# LKS32MC08x register map
Vendor: Linko Ltd.; Series: LKS32MC08x; File version: 1.0
ARM 32-bit Cortex-M0 Microcontroller based device, CPU clock up to 96MHz, etc.
CPU: CM0 r1p0, little endian, MPU, no FPU, 3 interrupt priority bits
Registers are 32-bit, read-write, reset 0x0 unless marked. A register's access mark holds for its fields unless they carry their own. Offsets are from the block's base; lines under a group give offsets from that group; [hi:lo] are bit positions; {n}, {i} and the like mark numbered series; 'fields as' and 'values as' point back to an identical list; <NAME> marks a mode.

## Memory map
0x40000000 SYS size 0x100 — SYS registers
0x40000400 FLASH size 0x40 — FLASH registers
0x40010000 SPI size 0x100 — SPI registers
0x40010400 I2C size 0x100 — I2C registers
0x40010C00 CMP size 0x100 — CMP registers
0x40011000 HALL size 0x100 — HALL registers
0x40011400 ADC0 size 0x100 — ADC0 registers
0x40011800 TIMER0 size 0x20 — TIMER0 registers
0x40011820 TIMER1 size 0x20 — TIMER1 registers
0x40011840 TIMER2 size 0x20 — TIMER2 registers
0x40011860 TIMER3 size 0x20 — TIMER3 registers
0x40011880 ENCODER0 size 0x10 — ENCODER0 registers
0x40011890 ENCODER1 size 0x10 — ENCODER1 registers
0x400118A0 UTIMER_CTRL size 0x60 — UTIMER_CTRL registers
0x40011C00 MCPWM size 0x100 — MCPWM registers
0x40012000 GPIO size 0x200 — GPIO registers
0x40012400 CRC size 0x100 — CRC registers
0x40012800 UART0 size 0x100 — UART0 registers
0x40012C00 UART1 size 0x100 — UART1 registers
0x40013000 DMA size 0x100 — DMA registers
0x40013400 CAN size 0x2000 — CAN registers
0x40013800 SIF size 0x100 — SIF registers
0x40014000 DSP size 0x2000 — DSP registers

## Interrupts
0 TIMER0
1 TIMER1
2 TIMER2
3 TIMER3
4 ENCODER0
5 ENCODER1
6 I2C0 (I2C)
7 GPIO
8 UART0
9 HALL
10 SPI0 (SPI)
11 ADC0
12 DSP
13 MCPWM
14 UART1
15 CMP
16 WAKE (SYS)
17 PWRDN (SYS)
18 DMA
19 CAN
20 SIF

## FLASH — FLASH registers
Base 0x40000400
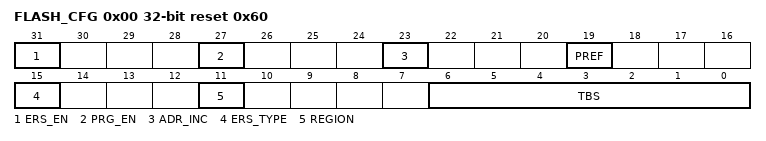
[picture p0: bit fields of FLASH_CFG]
0x00 FLASH_CFG reset 0x60 — Flash Configure Register
  [31] ERS_EN — Flash erase operation is enabled or not
    0=Disabled (Erase is disabled); 1=Enabled (Erase is enabled)
  [27] PRG_EN — Flash program operation is enabled or not
    0=Disabled (Program is disabled); 1=Enabled (Program is enabled)
  [23] ADR_INC — Flash address is incremented automatically or not during sequent access
    0=Disabled (Address incrementation is disabled); 1=Enabled (Address incrementation is enabled)
  [19] PREF — Prefetch Function Enable or Disable
    0=Disabled (Prefetch is disabled); 1=Enabled (Prefetch is enabled)
  [15] ERS_TYPE — Erase Type: Sector/Full
    0=Sector Erase; 1=Full Erase
  [11] REGION — Access Main or NVR
    0=Main access; 1=NVR (NVR access)
  [6:0] TBS — Program/Erase timer baseline
    96=96MHz (P/E Timer value @ 96Mhz); 47=48MHz (P/E Timer value @ 48Mhz); 23=24MHz (P/E Timer value @ 24Mhz); 11=12MHz (P/E Timer value @ 12Mhz)
0x04 FLASH_ADDR — Flash Access Address Register
0x08 FLASH_WDATA — Flash Write Data Register
0x0C FLASH_RDATA ro — Flash Write Data Register
0x10 FLASH_ERASE wo — Flash Register Trig Erase Operation(Write 0x7654DCBA to Trig Erase Operation)
0x14 FLASH_PROTECT ro — Read to update Flash Protection Status
0x18 FLASH_READY ro (reset mask 0x80000000) — Flash Busy/Idle Status

## SPI — SPI registers
Base 0x40010000
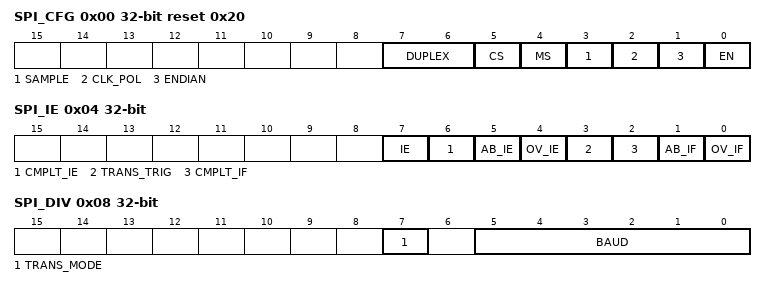
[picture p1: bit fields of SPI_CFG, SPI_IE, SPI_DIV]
0x00 SPI_CFG reset 0x20 — SPI Control Register
  [7:6] DUPLEX — Half duplex config
    3=DuplexRx (Duplex with Rx only); 2=DuplexTx (Duplex with Tx only); 1=NoDuplex; 0=NoDuplex
  [5] CS — spi chip select control big
    0=Zero (if in spi slave mode, always selected); 1=FromMaster (if in spi slave mode, SPI_CS signal is from spi master)
  [4] MS — spi device is master or slave
    0=slave mode; 1=master mode
  [3] SAMPLE — spi sample time control bit
    0=Value (positive clock edge sample data, negative clock edge send data); 1=Value (positive clock edge send data, negative clock edge sample data)
  [2] CLK_POL — clock polarity control bit
    0=LOW (clock default value is low); 1=HIGH (clock default value is high)
  [1] ENDIAN — spi data endian control bit
    0=BIG (big endian mode, most significant bit sent first); 1=LITTLE (little endian mode, least significant bit sent first)
  [0] EN — spi enable control bit
    0=Disabled (disable spi module); 1=Enabled (enable spi module)
0x04 SPI_IE — SPI Interrupt Enable
  [7] IE — Interrupt Enable
    0=Disabled (SPI interrupt is disabled); 1=Enabled (SPI interrupt is enabled)
  [6] CMPLT_IE — Transfer Complete Interrupt Enable
    0=Disabled (SPI transfer complete interrupt is disabled); 1=Enabled (SPI transfer complete interrupt is enabled)
  [5] AB_IE — Abnormal Interrupt Enable
    0=Disabled (SPI abnormal interrupt is disabled); 1=Enabled (SPI abnormal interrupt is enabled)
  [4] OV_IE — Overflow Interrupt Enable
    0=Disabled (SPI overflow interrupt is disabled); 1=Enabled (SPI overflow interrupt is enabled)
  [3] TRANS_TRIG — Trigger Source
    0=Internal (Trigger comes from internal source. Only active in master mode); 1=External (Trigger comes from external source)
  [2] CMPLT_IF — Transfer Complete Interrupt
    0=Clear (SPI transfer complete interrupt is cleared); 1=Set (SPI transfer complete interrupt is set)
  [1] AB_IF — Abnormal Interrupt
    0=Clear (SPI abnormal interrupt is cleared); 1=Set (SPI abnormal interrupt is set)
  [0] OV_IF — Overflow Interrupt
    0=Clear (SPI overflow interrupt is cleared); 1=Set (SPI overflow interrupt is set)
0x08 SPI_DIV — SPI Clock Division
  [7] TRANS_MODE — by DMA or CPU
    0=DMA (Transfer by DMA); 1=CPU (Transfer by CPU)
  [5:0] BAUD — SPI baudrate = sys_clk/(2*BAUD+1) BAUD should be larger than 3
0x0C SPI_TX_DATA
0x10 SPI_RX_DATA
0x14 SPI_SIZE — SPI Transfer size in bytes

## Licence text in the file
ARM Limited (ARM) is supplying this software for use with Cortex-M processor based microcontroller, but can be equally used for other suitable processor architectures. This file can be freely distributed. Modifications to this file shall be clearly marked. . THIS SOFTWARE IS PROVIDED "AS IS". NO WARRANTIES, WHETHER EXPRESS, IMPLIED. OR STATUTORY, INCLUDING, BUT NOT LIMITED TO, IMPLIED WARRANTIES OF. MERCHANTABILITY AND FITNESS FOR A PARTICULAR PURPOSE APPLY TO THIS SOFTWARE. ARM SHALL NOT, IN ANY CIRCUMSTANCES, BE LIABLE FOR SPECIAL, INCIDENTAL, OR. CONSEQUENTIAL DAMAGES, FOR ANY REASON WHATSOEVER.

## Notices in the file
Copyright (C) 2012-2014 ARM Limited. All rights reserved.
Purpose: System Viewer Description (SVD) Example (Schema Version 1.1)
This is a description of a none-existent and incomplete device
for demonstration purposes only.
Redistribution and use in source and binary forms, with or without
modification, are permitted provided that the following conditions are met:
- Redistributions of source code must retain the above copyright
notice, this list of conditions and the following disclaimer.
- Redistributions in binary form must reproduce the above copyright
notice, this list of conditions and the following disclaimer in the
documentation and/or other materials provided with the distribution.
- Neither the name of ARM nor the names of its contributors may be used
to endorse or promote products derived from this software without
specific prior written permission.
THIS SOFTWARE IS PROVIDED BY THE COPYRIGHT HOLDERS AND CONTRIBUTORS "AS IS"
AND ANY EXPRESS OR IMPLIED WARRANTIES, INCLUDING, BUT NOT LIMITED TO, THE
ARE DISCLAIMED. IN NO EVENT SHALL COPYRIGHT HOLDERS AND CONTRIBUTORS BE
LIABLE FOR ANY DIRECT, INDIRECT, INCIDENTAL, SPECIAL, EXEMPLARY, OR
CONSEQUENTIAL DAMAGES (INCLUDING, BUT NOT LIMITED TO, PROCUREMENT OF
SUBSTITUTE GOODS OR SERVICES; LOSS OF USE, DATA, OR PROFITS; OR BUSINESS
INTERRUPTION) HOWEVER CAUSED AND ON ANY THEORY OF LIABILITY, WHETHER IN
CONTRACT, STRICT LIABILITY, OR TORT (INCLUDING NEGLIGENCE OR OTHERWISE)
ARISING IN ANY WAY OUT OF THE USE OF THIS SOFTWARE, EVEN IF ADVISED OF THE
POSSIBILITY OF SUCH DAMAGE.
